# MKV46F16 register map
Vendor: Freescale Semiconductor, Inc.; Series: Kinetis_V; File version: 1.6
CPU: CM4 r0p1, little endian, no MPU, FPU, VTOR, 4 interrupt priority bits
Registers are 32-bit, read-write, reset 0x0 unless marked. A register's access mark holds for its fields unless they carry their own. Offsets are from the block's base; [hi:lo] are bit positions; {n}, {i} and the like mark numbered series; 'fields as' and 'values as' point back to an identical list; <NAME> marks a mode.

## ADC — Analog to digital converter
Base 0x4005C000; register names take the prefix ADC_
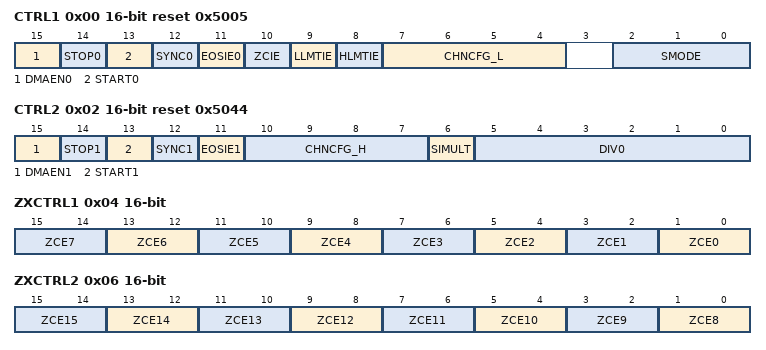
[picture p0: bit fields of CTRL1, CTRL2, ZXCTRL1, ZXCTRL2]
0x00 CTRL1 16-bit reset 0x5005 — ADC Control Register 1
  [15] DMAEN0 — DMA enable
    0=DMA is not enabled; 1=DMA is enabled
  [14] STOP0 — Stop
    0=Normal operation; 1=Stop mode
  [13] START0 wo — START0 Conversion
    0=No action; 1=Start command is issued
  [12] SYNC0 — SYNC0 Enable
    0=Scan is initiated by a write to CTRL1[START0] only; 1=Use a SYNC0 input pulse or CTRL1[START0] to initiate a scan
  [11] EOSIE0 — End Of Scan Interrupt Enable
    0=Interrupt disabled; 1=Interrupt enabled
  [10] ZCIE — Zero Crossing Interrupt Enable
    0=Interrupt disabled; 1=Interrupt enabled
  [9] LLMTIE — Low Limit Interrupt Enable
    0=Interrupt disabled; 1=Interrupt enabled
  [8] HLMTIE — High Limit Interrupt Enable
    0=Interrupt disabled; 1=Interrupt enabled
  [7:4] CHNCFG_L — CHCNF (Channel Configure Low) bits
  [2:0] SMODE — ADC Scan Mode Control
    0=Once (single) sequential; 1=Once parallel; 2=Loop sequential; 3=Loop parallel; 4=Triggered sequential; 5=Triggered parallel (default)
0x02 CTRL2 16-bit reset 0x5044 — ADC Control Register 2
  [15] DMAEN1 — DMA enable
    0=DMA is not enabled; 1=DMA is enabled
  [14] STOP1 — Stop
    0=Normal operation; 1=Stop mode
  [13] START1 wo — START1 Conversion
    0=No action; 1=Start command is issued
  [12] SYNC1 — SYNC1 Enable
    0=B converter parallel scan is initiated by a write to CTRL2[START1] bit only; 1=Use a SYNC1 input pulse or CTRL2[START1] bit to initiate a B converter parallel scan
  [11] EOSIE1 — End Of Scan Interrupt Enable
    0=Interrupt disabled; 1=Interrupt enabled
  [10:7] CHNCFG_H — CHCNF (Channel Configure High) bits
  [6] SIMULT — Simultaneous mode
    0=Parallel scans done independently; 1=Parallel scans done simultaneously (default)
  [5:0] DIV0 — Clock Divisor Select
0x04 ZXCTRL1 16-bit — ADC Zero Crossing Control 1 Register
  [all] fields
    0=Zero Crossing disabled; 1=Zero Crossing enabled for positive to negative sign change; 2=Zero Crossing enabled for negative to positive sign change; 3=Zero Crossing enabled for any sign change
  [2n+1:2n] ZCE{n} (n=0..7) — Zero crossing enable {n}
0x06 ZXCTRL2 16-bit — ADC Zero Crossing Control 2 Register
  [all] fields
    values as the fields of ZXCTRL1
  [2n-15:2n-16] ZCE{n} (n=8..15) — Zero crossing enable {n}
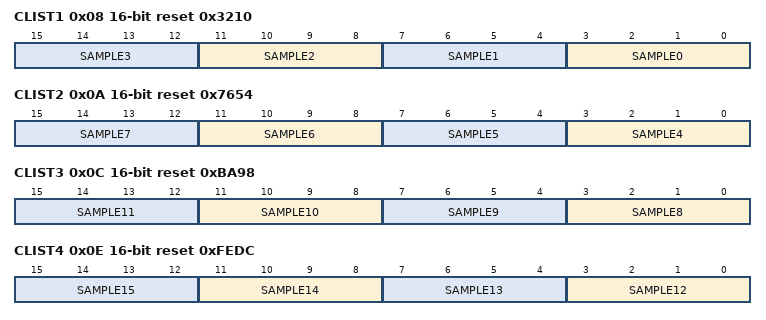
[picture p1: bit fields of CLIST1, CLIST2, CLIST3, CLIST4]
0x08 CLIST1 16-bit reset 0x3210 — ADC Channel List Register 1
  [all] fields
    0=Single Ended: ADCA_CH0, Differential: ADCA_CH0+, ADCA_CH1-; 1=Single Ended: ADCA_CH1, Differential: ADCA_CH0+, ADCA_CH1-; 2=Single Ended: ADCA_CH2, Differential: ADCA_CH2+, ADCA_CH3-; 3=Single Ended: ADCA_CH3, Differential: ADCA_CH2+, ADCA_CH3-; 4=Single Ended: ADCA_CH4, Differential: ADCA_CH4+, ADCA_CH5-; 5=Single Ended: ADCA_CH5, Differential: ADCA_CH4+, ADCA_CH5-; 6=Single Ended: ADCA_CH6, Differential: ADCA_CH6+, ADCA_CH7-; 7=Single Ended: ADCA_CH7, Differential: ADCA_CH6+, ADCA_CH7-; 8=Single Ended: ADCB_CH0, Differential: ADCB_CH0+, ADCB_CH1-; 9=Single Ended: ADCB_CH1, Differential: ADCB_CH0+, ADCB_CH1-; 10=Single Ended: ADCB_CH2, Differential: ADCB_CH2+, ADCB_CH3-; 11=Single Ended: ADCB_CH3, Differential: ADCB_CH2+, ADCB_CH3-; 12=Single Ended: ADCB_CH4, Differential: ADCB_CH4+, ADCB_CH5-; 13=Single Ended: ADCB_CH5, Differential: ADCB_CH4+, ADCB_CH5-; 14=Single Ended: ADCB_CH6, Differential: ADCB_CH6+, ADCB_CH7-; 15=Single Ended: ADCB_CH7, Differential: ADCB_CH6+, ADCB_CH7-
  [4n+3:4n] SAMPLE{n} (n=0..3) — Sample Field {n}
0x0A CLIST2 16-bit reset 0x7654 — ADC Channel List Register 2
  [all] fields
    values as the fields of CLIST1
  [4n-13:4n-16] SAMPLE{n} (n=4..7) — Sample Field {n}
0x0C CLIST3 16-bit reset 0xBA98 — ADC Channel List Register 3
  [all] fields
    values as the fields of CLIST1
  [4n-29:4n-32] SAMPLE{n} (n=8..11) — Sample Field {n}
0x0E CLIST4 16-bit reset 0xFEDC — ADC Channel List Register 4
  [all] fields
    values as the fields of CLIST1
  [4n-45:4n-48] SAMPLE{n} (n=12..15) — Sample Field {n}
0x10 SDIS 16-bit reset 0xF0F0 — ADC Sample Disable Register
  [15:0] DS — Disable Sample Bits
    0=SAMPLEx channel is enabled for ADC scan; 1=SAMPLEx channel is disabled for ADC scan and corresponding channels after SAMPLEx also doesn not occur in an ADC scan
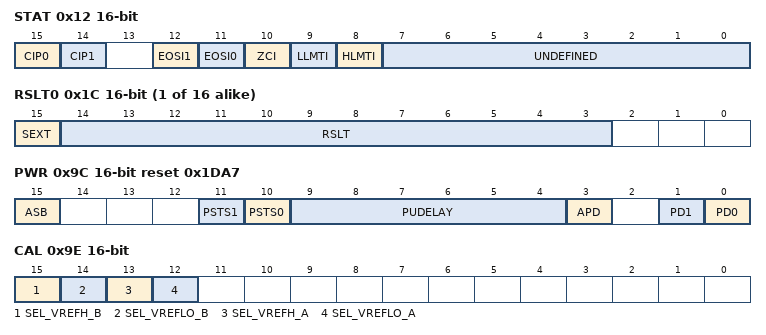
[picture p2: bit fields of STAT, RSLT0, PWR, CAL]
0x12 STAT 16-bit — ADC Status Register
  [15] CIP0 ro — Conversion in Progress
    0=Idle state; 1=A scan cycle is in progress. The ADC will ignore all sync pulses or start commands
  [14] CIP1 ro — Conversion in Progress
    values as CIP0
  [12] EOSI1 — End of Scan Interrupt
    0=A scan cycle has not been completed, no end of scan IRQ pending; 1=A scan cycle has been completed, end of scan IRQ pending
  [11] EOSI0 — End of Scan Interrupt
    values as EOSI1
  [10] ZCI ro — Zero Crossing Interrupt
    0=No zero crossing interrupt request; 1=Zero crossing encountered, IRQ pending if CTRL1[ZCIE] is set
  [9] LLMTI ro — Low Limit Interrupt
    0=No low limit interrupt request; 1=Low limit exceeded, IRQ pending if CTRL1[LLMTIE] is set
  [8] HLMTI ro — High Limit Interrupt
    0=No high limit interrupt request; 1=High limit exceeded, IRQ pending if CTRL1[HLMTIE] is set
  [7:0] UNDEFINED ro — This read-only bitfield is undefined and will always contain random data.
0x14 RDY 16-bit ro — ADC Ready Register
  [15:0] RDY — Ready Sample
    0=Sample not ready or has been read; 1=Sample ready to be read
0x16 LOLIMSTAT 16-bit — ADC Low Limit Status Register
  [15:0] LLS — Low Limit Status Bits
0x18 HILIMSTAT 16-bit — ADC High Limit Status Register
  [15:0] HLS — High Limit Status Bits
0x1A ZXSTAT 16-bit — ADC Zero Crossing Status Register
  [15:0] ZCS — Zero Crossing Status
    0=Either: A sign change did not occur in a comparison between the current channelx result and the previous channelx result, or Zero crossing control is disabled for channelx in the zero crossing control register, ZXCTRL; 1=In a comparison between the current channelx result and the previous channelx result, a sign change condition occurred as defined in the zero crossing control register (ZXCTRL)
{0x1C+2i} RSLT{i} (i=0..15) 16-bit — ADC Result Registers with sign extension
  [15] SEXT ro — Sign Extend
  [14:3] RSLT — Digital Result of the Conversion
{0x3C+2i} LOLIM{i} (i=0..15) 16-bit — ADC Low Limit Registers
  [14:3] LLMT — Low Limit Bits
{0x5C+2i} HILIM{i} (i=0..15) 16-bit reset 0x7FF8 — ADC High Limit Registers
  [14:3] HLMT — High Limit Bits
{0x7C+2i} OFFST{i} (i=0..15) 16-bit — ADC Offset Registers
  [14:3] OFFSET — ADC Offset Bits
0x9C PWR 16-bit reset 0x1DA7 — ADC Power Control Register
  [15] ASB — Auto Standby
    0=Auto standby mode disabled; 1=Auto standby mode enabled
  [11] PSTS1 ro — ADC Converter B Power Status
    0=ADC Converter B is currently powered up; 1=ADC Converter B is currently powered down
  [10] PSTS0 ro — ADC Converter A Power Status
    0=ADC Converter A is currently powered up; 1=ADC Converter A is currently powered down
  [9:4] PUDELAY — Power Up Delay
  [3] APD — Auto Powerdown
    0=Auto Powerdown Mode is not active; 1=Auto Powerdown Mode is active
  [1] PD1 — Manual Power Down for Converter B
    0=Power Up ADC converter B; 1=Power Down ADC converter B
  [0] PD0 — Manual Power Down for Converter A
    0=Power Up ADC converter A; 1=Power Down ADC converter A
0x9E CAL 16-bit — ADC Calibration Register
  [15] SEL_VREFH_B — Select V REFH Source
    0=VREFH pad; 1=ADCB_CH2
  [14] SEL_VREFLO_B — Select V REFLO Source
    0=VREFL pad; 1=ADCB_CH3
  [13] SEL_VREFH_A — Select V REFH Source
    0=VREFH pad; 1=ADCA_CH2
  [12] SEL_VREFLO_A — Select V REFLO Source
    0=VREFL pad; 1=ADCA_CH3
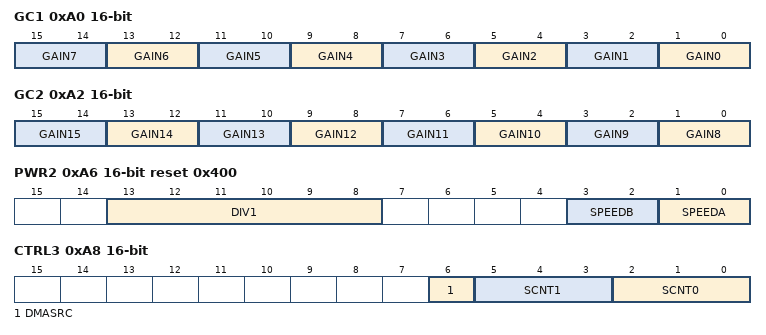
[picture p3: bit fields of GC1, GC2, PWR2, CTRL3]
0xA0 GC1 16-bit — Gain Control 1 Register
  [all] fields
    0=x1 amplification; 1=x2 amplification; 2=x4 amplification
  [2n+1:2n] GAIN{n} (n=0..7) — Gain Control Bit {n}
0xA2 GC2 16-bit — Gain Control 2 Register
  [all] fields
    0=x1 amplification; 1=x2 amplification; 2=x4 amplification
  [2n-15:2n-16] GAIN{n} (n=8..15) — Gain Control Bit {n}
0xA4 SCTRL 16-bit — ADC Scan Control Register
  [15:0] SC — Scan Control Bits
    0=Perform sample immediately after the completion of the current sample; 1=Delay sample until a new sync input occurs
0xA6 PWR2 16-bit reset 0x400 — ADC Power Control Register
  [13:8] DIV1 — Clock Divisor Select
  [3:2] SPEEDB — ADCB Speed Control Bits
    0=Conversion clock frequency <= 6.25 MHz; current consumption per converter = 6 mA; 1=Conversion clock frequency <= 12.5 MHz; current consumption per converter = 10.8 mA; 2=Conversion clock frequency <= 18.75 MHz; current consumption per converter = 18 mA; 3=Conversion clock frequency <= 25 MHz; current consumption per converter = 25.2 mA
  [1:0] SPEEDA — ADCA Speed Control Bits
    values as SPEEDB
0xA8 CTRL3 16-bit — ADC Control Register 3
  [6] DMASRC — DMA Trigger Source
    0=DMA trigger source is end of scan interrupt; 1=DMA trigger source is RDY bits
  [5:3] SCNT1 — Sample Window Count 1
  [2:0] SCNT0 — Sample Window Count 0
0xAA SCHLTEN 16-bit — ADC Scan Interrupt Enable Register
  [15:0] SCHLTEN — Scan Interrupt Enable
    0=Scan interrupt is not enabled for this sample; 1=Scan interrupt is enabled for this sample
